# D2522AA register map
Vendor: Dialog; Series: D2522AA; File version: 1.2
CPU: CM0 r1p0, little endian, MPU, FPU, 3 interrupt priority bits
Registers are 32-bit, read-write, reset 0x0 unless marked. A register's access mark holds for its fields unless they carry their own. Offsets are from the block's base; [hi:lo] are bit positions; {n}, {i} and the like mark numbered series; 'fields as' and 'values as' point back to an identical list.

## GPIO — GPIO registers
Base 0x50020A00
0x00 P0_DATA_REG reset 0x1410 (reset mask 0x7FFFFFFF) — P0 Data input / output Register
  [31:0] P0_DATA — Set P0 output register when written; Returns the value of P0 port when read
0x04 P1_DATA_REG — P1 Data input / output Register
  [22:0] P1_DATA — Set P1 output register when written; Returns the value of P1 port when read
0x08 P0_SET_DATA_REG (reset mask 0x7FFFFFFF) — P0 Set port pins Register
  [31:0] P0_SET wo — Writing a 1 to P0[y] sets P0[y] to 1. Writing 0 is discarded; Reading returns 0
0x0C P1_SET_DATA_REG — P1 Set port pins Register
  [22:0] P1_SET wo — Writing a 1 to P1[y] sets P1[y] to 1. Writing 0 is discarded; Reading returns 0
0x10 P0_RESET_DATA_REG (reset mask 0x7FFFFFFF) — P0 Reset port pins Register
  [31:0] P0_RESET wo — Writing a 1 to P0[y] sets P0[y] to 0. Writing 0 is discarded; Reading returns 0
0x14 P1_RESET_DATA_REG — P1 Reset port pins Register
  [22:0] P1_RESET wo — Writing a 1 to P1[y] sets P1[y] to 0. Writing 0 is discarded; Reading returns 0
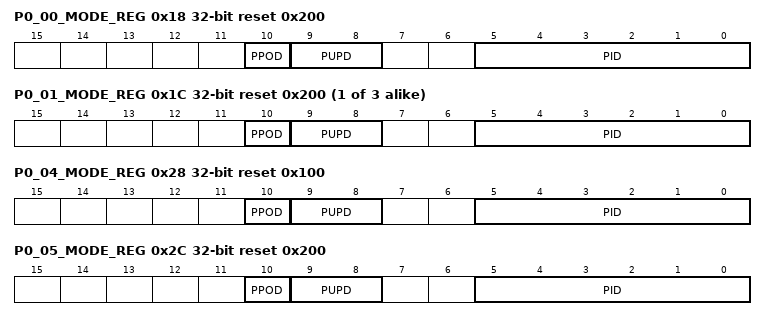
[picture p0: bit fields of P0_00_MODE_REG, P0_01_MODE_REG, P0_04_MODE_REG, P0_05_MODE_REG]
0x18 P0_00_MODE_REG reset 0x200 — P0_00 Mode Register
  [10] PPOD — 0: Push pull 1: Open drain
  [9:8] PUPD — 00 = Input, no resistors selected 01 = Input, pull-up selected 10 = Input, pull-down selected 11 = Output, no resistors selected In ADC mode, these bits are don't care
  [5:0] PID — Function of port: 0: GPIO (see also the PUPD bit-field) 1: UART_RX 2: UART_TX 3: UART2_RX 4: UART2_TX 5: UART2_CTSN 6: UART2_RTSN 7: UART3_RX 8: UART3_TX 9: UART3_CTSN 10: UART3_RTSN 11: ISO_CLK 12: ISO_DATA 13: SPI_DI 14: SPI_DO 15: SPI_CLK16: SPI_EN 17: SPI2_DI 18: SPI2_DO 19: SPI2_CLK 20: SPI2_EN 21: I2C_SCL 22: I2C_SDA 23: I2C2_SCL 24: I2C2_SDA 25: USB_SOF 26: ADC (dedicated pins) 27: USB (dedicated pins) 28: PCM_DI 29: PCM_DO 30: PCM_FSC 31: PCM_CLK 32: PDM_DATA 33: PDM_CLK 34: COEX_EXT_ACT0 35: COEX_SMART_ACT 36: COEX_SMART_PRI 37: PORT0_DCF 38: PORT1_DCF 39: PORT2_DCF 40: PORT3_DCF 41: PORT4_DCF 42: CLOCK (dedicated pins, see also GPIO_CLK_SEL_REG) 43: PG (dedicated pins) 44: LCD (dedicated pins) 45: LCD_SPI_DC 46: LCD_SPI_DO 47: LCD_SPI_CLK 48: LCD_SPI_EN 49: TIM_PWM 50: TIM2_PWM 51: TIM_1SHOT 52: TIM2_1SHOT 53: TIM3_PWM 54: TIM4_PWM 55: Reserved 56: CMAC_DIAG0 57: CMAC_DIAG1 58: CMAC_DIAG2 59: CMAC_DIAGX (dedicated pins)
{0x18+4i} P0_{i:02}_MODE_REG reset 0x200 (i=1..3) — P0_{i:02} Mode Register
  [10] PPOD — 0: Push pull 1: Open drain
  [9:8] PUPD — 00 = Input, no resistors selected 01 = Input, pull-up selected 10 = Input, pull-down selected 11 = Output, no resistors selected In ADC mode, these bits are don't care
  [5:0] PID — See P0_00_MODE_REG[PID]
0x28 P0_04_MODE_REG reset 0x100 — P0_04 Mode Register
  fields as P0_01_MODE_REG
0x2C P0_05_MODE_REG reset 0x200 — P0_05 Mode Register
  fields as P0_01_MODE_REG
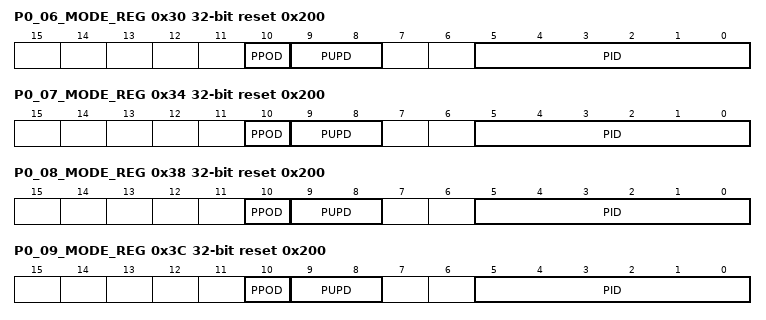
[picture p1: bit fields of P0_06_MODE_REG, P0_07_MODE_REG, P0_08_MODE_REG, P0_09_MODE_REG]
0x30 P0_06_MODE_REG reset 0x200 — P0_06 Mode Register
  fields as P0_01_MODE_REG
0x34 P0_07_MODE_REG reset 0x200 — P0_07 Mode Register
  [10] PPOD — 0: Push pull 1: Open drain
  [9:8] PUPD — 00 = Input, no resistors selected 01 = Input, pull-up selected 10 = Input, pull-down selected 11 = Output, no resistors selected In ADC mode, these bits are don't care.
  [5:0] PID — See P0_00_MODE_REG[PID]
0x38 P0_08_MODE_REG reset 0x200 — P0_08 Mode Register
  [10] PPOD — 0: Push pull 1: Open drain
  [9:8] PUPD — 00 = Input, no resistors selected 01 = Input, pull-up selected 10 = Input, pull-down selected 11 = Output, no resistors selected In ADC mode, these bits are don't care.
  [5:0] PID — See P00_MODE_REG[PID]
0x3C P0_09_MODE_REG reset 0x200 — P0_09 Mode Register
  fields as P0_08_MODE_REG
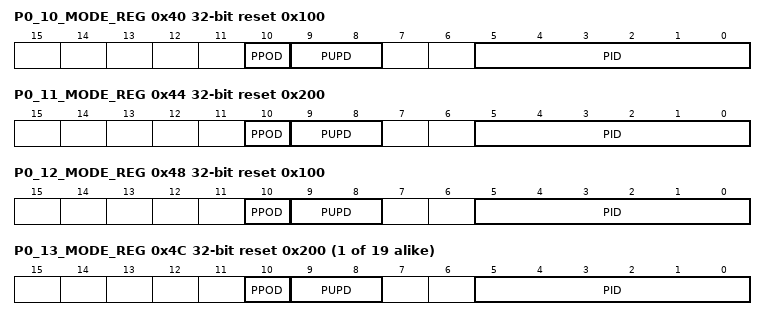
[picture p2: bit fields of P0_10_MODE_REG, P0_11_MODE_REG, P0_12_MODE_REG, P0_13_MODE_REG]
0x40 P0_10_MODE_REG reset 0x100 — P0_10 Mode Register
  fields as P0_07_MODE_REG
0x44 P0_11_MODE_REG reset 0x200 — P0_11 Mode Register
  fields as P0_07_MODE_REG
0x48 P0_12_MODE_REG reset 0x100 — P0_12 Mode Register
  fields as P0_07_MODE_REG
{0x18+4i} P0_{i}_MODE_REG reset 0x200 (i=13..31) — P0_{i} Mode Register
  fields as P0_07_MODE_REG
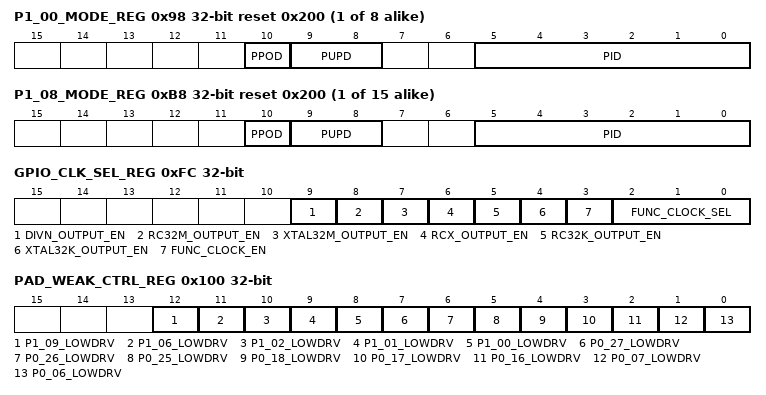
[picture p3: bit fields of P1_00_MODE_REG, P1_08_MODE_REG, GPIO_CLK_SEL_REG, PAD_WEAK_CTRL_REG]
{0x98+4i} P1_{i:02}_MODE_REG reset 0x200 (i=0..7) — P1_{i:02} Mode Register
  fields as P0_01_MODE_REG
{0x98+4i} P1_{i:02}_MODE_REG reset 0x200 (i=8..22) — P1_{i:02} Mode Register
  fields as P0_07_MODE_REG
0xF4 P0_PADPWR_CTRL_REG (reset mask 0x7FFFFFFF) — P0 Output Power Control Register
  [31:6] P0_OUT_CTRL — 0 = P0_x port output is powered by the V30 rail (default) 1 = P0_x port output is powered by the 1V8P rail bit x controls the power supply of P0[x]
0xF8 P1_PADPWR_CTRL_REG — P1 Output Power Control Register
  [22:0] P1_OUT_CTRL — 0 = P1_x port output is powered by the V30 rail (default) 1 = P1_x port output is powered by the 1V8P rail bit x controls the power supply of P1[x]
0xFC GPIO_CLK_SEL_REG — Select which clock to map on ports P0/P1
  [9] DIVN_OUTPUT_EN — DIVN output enable bit-field. When set, it enables the mapping of DIVN clock on dedicated GPIO (P0_15). The specific GPIO must be configured as GPIO output.
  [8] RC32M_OUTPUT_EN — RC32M output enable bit-field. When set, it enables the mapping of RC32M clock on dedicated GPIO (P0_13). The specific GPIO must be configured as GPIO output.
  [7] XTAL32M_OUTPUT_EN — XTALK32M output enable bit-field. When set, it enables the mapping of XTAL32M clock on dedicated GPIO (P0_12). The specific GPIO must be configured as GPIO output.
  [6] RCX_OUTPUT_EN — RCX output enable bit-field. When set, it enables the mapping of RCX clock on dedicated GPIO (P0_16). The specific GPIO must be configured as GPIO output.
  [5] RC32K_OUTPUT_EN — RC32K output enable bit-field. When set, it enables the mapping of RC32K clock on dedicated GPIO (P0_17). The specific GPIO must be configured as GPIO output.
  [4] XTAL32K_OUTPUT_EN — XTALK32K output enable bit-field. When set, it enables the mapping of XTAL32K clock on dedicated GPIO (P0_14).The specific GPIO must be configured as GPIO output.
  [3] FUNC_CLOCK_EN — If set, it enables the mapping of the selected clock signal, according to FUNC_CLOCK_SEL bit-field.
  [2:0] FUNC_CLOCK_SEL — Select which clock to map when PID = FUNC_CLOCK. 0x0: XTAL32K 0x1: RC32K 0x2: RCX 0x3: XTAL32M 0x4: RC32M 0x5: DIVN 0x6: Reserved 0x7: Reserved
0x100 PAD_WEAK_CTRL_REG — Weak Pads Control Register
  [12] P1_09_LOWDRV — 0 = Normal operation 1 = Reduces the driving strength of P1_09 pad Note: This mode should be coupled with the selection of VDD1V8P supply rail for the specific pad (see also the description of P1_PADPWDR_CTRL_REG).
  [11] P1_06_LOWDRV — 0 = Normal operation 1 = Reduces the driving strength of P1_06 pad Note: This mode should be coupled with the selection of VDD1V8P supply rail for the specific pad (see also the description of P1_PADPWDR_CTRL_REG).
  [10] P1_02_LOWDRV — 0 = Normal operation 1 = Reduces the driving strength of P1_02 pad Note: This mode should be coupled with the selection of VDD1V8P supply rail for the specific pad (see also the description of P1_PADPWDR_CTRL_REG).
  [9] P1_01_LOWDRV — 0 = Normal operation 1 = Reduces the driving strength of P1_01 pad Note: This mode should be coupled with the selection of VDD1V8P supply rail for the specific pad (see also the description of P1_PADPWDR_CTRL_REG).
  [8] P1_00_LOWDRV — 0 = Normal operation 1 = Reduces the driving strength of P1_00 pad Note: This mode should be coupled with the selection of VDD1V8P supply rail for the specific pad (see also the description of P1_PADPWDR_CTRL_REG).
  [7] P0_27_LOWDRV — 0 = Normal operation 1 = Reduces the driving strength of P0_27 pad Note: This mode should be coupled with the selection of VDD1V8P supply rail for the specific pad (see also the description of P0_PADPWDR_CTRL_REG).
  [6] P0_26_LOWDRV — 0 = Normal operation 1 = Reduces the driving strength of P0_26 pad Note: This mode should be coupled with the selection of VDD1V8P supply rail for the specific pad (see also the description of P0_PADPWDR_CTRL_REG).
  [5] P0_25_LOWDRV — 0 = Normal operation 1 = Reduces the driving strength of P0_25 pad Note: This mode should be coupled with the selection of VDD1V8P supply rail for the specific pad (see also the description of P0_PADPWDR_CTRL_REG).
  [4] P0_18_LOWDRV — 0 = Normal operation 1 = Reduces the driving strength of P0_18 pad Note: This mode should be coupled with the selection of VDD1V8P supply rail for the specific pad (see also the description of P0_PADPWDR_CTRL_REG).
  [3] P0_17_LOWDRV — 0 = Normal operation 1 = Reduces the driving strength of P0_17 pad Note: This mode should be coupled with the selection of VDD1V8P supply rail for the specific pad (see also the description of P0_PADPWDR_CTRL_REG).
  [2] P0_16_LOWDRV — 0 = Normal operation 1 = Reduces the driving strength of P0_16 pad Note: This mode should be coupled with the selection of VDD1V8P supply rail for the specific pad (see also the description of P0_PADPWDR_CTRL_REG).
  [1] P0_07_LOWDRV — 0 = Normal operation 1 = Reduces the driving strength of P0_07 pad Note: This mode should be coupled with the selection of VDD1V8P supply rail for the specific pad (see also the description of P0_PADPWDR_CTRL_REG).
  [0] P0_06_LOWDRV — 0 = Normal operation 1 = Reduces the driving strength of P0_06 pad Note: This mode should be coupled with the selection of VDD1V8P supply rail for the specific pad (see also the description of P0_PADPWDR_CTRL_REG).
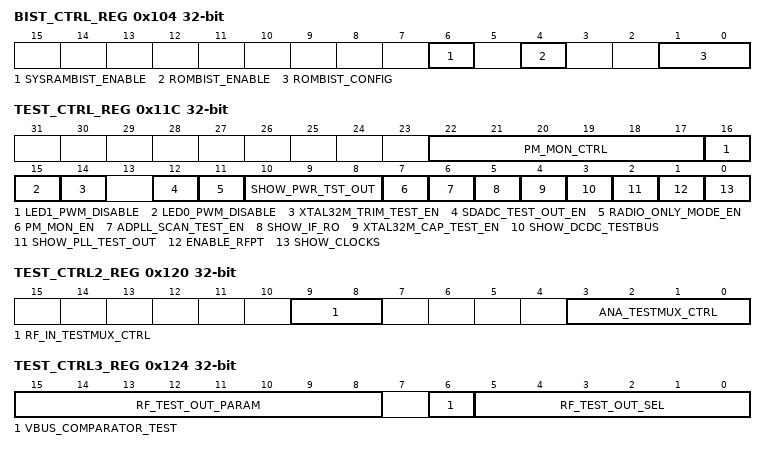
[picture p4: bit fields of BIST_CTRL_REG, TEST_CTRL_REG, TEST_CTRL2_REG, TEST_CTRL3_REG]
0x104 BIST_CTRL_REG — Memory BIST Control Register
  [6] SYSRAMBIST_ENABLE — Enable Memory Build In Self Test of all RAMs. Control of the MBIST is by means of a JTAG interface. 0: mission mode. 1: MBIST pinmapping: GPIO_P0_24: JTAG_TRST GPIO_P0_25: JTAG_TCK GPIO_P0_26: JTAG_TMS GPIO_P0_27: JTAG_TDI GPIO_P0_28: MBIST_ON GPIO_P0_29: MBIST_GO GPIO_P0_30: MBIST_DONE GPIO_P0_31: JTAG_TDO
  [4] ROMBIST_ENABLE — Enable the ROM bist
  [1:0] ROMBIST_CONFIG — Bist configuration for ROMBIST: 00 = Perform all 2 phases 01 = Perform only phase 1 10 = Perform only phase 2 11 = Reserved
0x108 RAMBIST_STATUS1_REG — RAM BIST Status Register
  [15] ROM_BIST_BUSY ro — status of internal signal "busy" of rom bist
0x10C RAMBIST_STATUS2_REG (reset mask 0x7FFF) — RAM BIST Status Register 2
0x110 RAMBIST_STATUS3_REG (reset mask 0x7) — RAM BIST Status Register 3
0x114 ROMBIST_RESULTL_REG — ROM BIST Status Register - 16 LSBs
  [15:0] ROMBIST_RESULTL ro — Read version of bist status, result[15:0]
0x118 ROMBIST_RESULTH_REG — ROM BIST Status Register - 16 MSBs
  [15:0] ROMBIST_RESULTH ro — Read version of bist status, result[31:16]
0x11C TEST_CTRL_REG — Test Control Register
  [22:17] PM_MON_CTRL — PM control bus ([7:0])
  [16] LED1_PWM_DISABLE — Disable PWM on LED1 driver, dutycycle LED1=100%
  [15] LED0_PWM_DISABLE — Disable PWM on LED0 driver, dutycycle LED0=100%
  [14] XTAL32M_TRIM_TEST_EN — 0: normal port function, 1: shows xtal32m_trim_sw2_isolated onto pin P1_6
  [12] SDADC_TEST_OUT_EN — 0: Normal operation, 1: Maps the Sigma-Delta ADC bitstream signal onto the P1_8 pin.
  [11] RADIO_ONLY_MODE_EN — 0: Normal operation, 1: Enables the Exposed Radio mode (Radio-only mode).
  [10:8] SHOW_PWR_TST_OUT — 0: Normal operation 1: P1[7:1] = ldo_1v8_flash_ret_enable, ldo_supply_vbat_ok, ldo_supply_usb_ok, ldo_1v8_pa_ret_enable, bandgap_bgr_ok, 0, ldo_vbat_ret_enable 2: P1[7:1] = ldo_vbat_ret_vref_hold, ldo_core_ok, pll_status_reg_isolated_1, ldo_radio_ok,ldo_1v8_pa_ok, ldo_1v8_flash_ok, ldo_supply_usb_enable 3: P1[7:1] = ldo_1v8_flash_ret_vref_hold, vbus_available, newbat, clear_newbat, ldo_1v8_pa_ret_vref_hold, 0, power_on_reset 4: P1[7:1] = comp_v18_pa_high, comp_v18_flash_high, comp_vdd_high, comp_vbus_low, comp_vbus_high, comp_v33_high, comp_vbat_ok 5: P1[7:1] = charge_gate_enable, bod_v18_pa_low, bod_v33_low, bod_v18_flash_low, bod_vdd_low, bod_vbat_low, bod_clk
  [7] PM_MON_EN — 0: Normal operation 1: Shows the PM_MON[3:0] bus on pins P0[25:22]
  [6] ADPLL_SCAN_TEST_EN — 0: Normal operation 1: Enables the ADPLL scan test signal, activating the respective scan mode.
  [5] SHOW_IF_RO — 0: Normal Port function. 1: Show IF filter Reference Oscillator I and Q signals. P10 = iff_ro_out_i P06 = iff_ro_out_q
  [4] XTAL32M_CAP_TEST_EN — 0: Normal Port function. 1: Shows xtal16m_cap_test_out output onto pins P1[3:2] Notes: - The control signal should go to the radio to enable this test mode. - This register should be zero during scan test!
  [3] SHOW_DCDC_TESTBUS — 0: normal port function 1: map the DCDC testbus [11:0] on the following GPIO's (MSB first): P23,P21,P20,P1[7:0],P07
  [2] SHOW_PLL_TEST_OUT — 0: normal port function 1: map pll_out_div_test_out on P06 and pll_loop_div_test_out on P10
  [1] ENABLE_RFPT — 0: normal port function 1: enable the RF Production Test Unit. Used to store RX ADC samples or PLL TDC samples in SRAM. See RFPT_CTRL_REG, RFPT_ADDR_REG and RFPT_LEN_REG for details.
  [0] SHOW_CLOCKS — 0: normal port function 1: show DIVN clock on P10
0x120 TEST_CTRL2_REG — Test Control Register 2
  [9:8] RF_IN_TESTMUX_CTRL — Connect the RF input testbus to pins: Switch 1 (bit 8) connects T0 of the radio test input bus to pin P1_6 Switch 2 (bit 9) connects T1 of the radio test input bus to pin P1_9 If this bit is 0, the switch is open (not conducting).
  [3:0] ANA_TESTMUX_CTRL — Control of analog test bus switches: Switch 1 connects T0 of the radio test output bus to P1_7 Switch 2 connects T1 of the radio test output bus to P1_10] Switch 3 connects T0 of the analog test output bus to P1_7 Switch 4 connects T1 of the analog test output bus to P1_10 0: all switches open 1: only switch 1 closed 2: only switch 2 closed 3: only switch 3 closed 4: only switch 4 closed 5: switches 1 & 2 closed 6: switches 1 & 4 closed 7: switches 2 & 3 closed 8: switches 3 & 4 closed
0x124 TEST_CTRL3_REG — Test Control Register 3
  [15:8] RF_TEST_OUT_PARAM — Select which test will be enabled on the block selected by the RF output testbus (see
  [6] VBUS_COMPARATOR_TEST — Control for the testability of VBUS input on V33 comparator
  [5:0] RF_TEST_OUT_SEL — Select a radio block to have its testbus connected to P1[1] and P1[2]. See Table 7 for more information. NOTE: all 0 represent no testmode and the testbusses are shorted to ground to prevent floating busses.
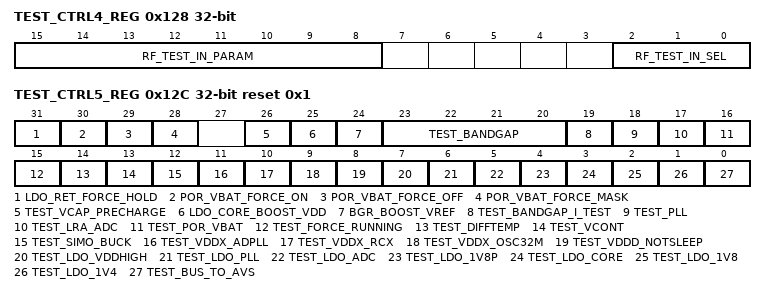
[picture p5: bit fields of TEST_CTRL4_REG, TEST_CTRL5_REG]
0x128 TEST_CTRL4_REG — Test Control Register 4
  [15:8] RF_TEST_IN_PARAM — Select which test will be enabled on the block selected by the RF output testbus (see
  [2:0] RF_TEST_IN_SEL — Select an RF block to have its test input connected to the input testbus at pins P0[0] and P0[3]. NOTE: all 0 represent no testmode and the testbusses are shorted to ground to prevent floating busses.
0x12C TEST_CTRL5_REG reset 0x1 (reset mask 0x7FFFFFFF) — Test Control Register 5
  [31] LDO_RET_FORCE_HOLD, [30] POR_VBAT_FORCE_ON, [29] POR_VBAT_FORCE_OFF, [28] POR_VBAT_FORCE_MASK, [26] TEST_VCAP_PRECHARGE, [25] LDO_CORE_BOOST_VDD, [24] BGR_BOOST_VREF, [23:20] TEST_BANDGAP, [19] TEST_BANDGAP_I_TEST, [18] TEST_PLL, [17] TEST_LRA_ADC, [16] TEST_POR_VBAT, [15] TEST_FORCE_RUNNING, [14] TEST_DIFFTEMP, [13] TEST_VCONT, [12] TEST_SIMO_BUCK, [11] TEST_VDDX_ADPLL, [10] TEST_VDDX_RCX, [9] TEST_VDDX_OSC32M, [8] TEST_VDDD_NOTSLEEP, [7] TEST_LDO_VDDHIGH, [6] TEST_LDO_PLL, [5] TEST_LDO_ADC, [4] TEST_LDO_1V8P, [3] TEST_LDO_CORE, [2] TEST_LDO_1V8, [1] TEST_LDO_1V4, [0] TEST_BUS_TO_AVS
